# ATSAMG53 register map
Vendor: Microchip Technology; Series: SAMG53; File version: 0
CPU: CM4 r0p1, little endian, MPU, FPU, 4 interrupt priority bits
Registers are 32-bit, read-write, reset 0x0 unless marked. A register's access mark holds for its fields unless they carry their own. Offsets are from the block's base; [hi:lo] are bit positions; {n}, {i} and the like mark numbered series; 'fields as' and 'values as' point back to an identical list.

## SPI — Serial Peripheral Interface
Base 0x40008000; register names take the prefix SPI_
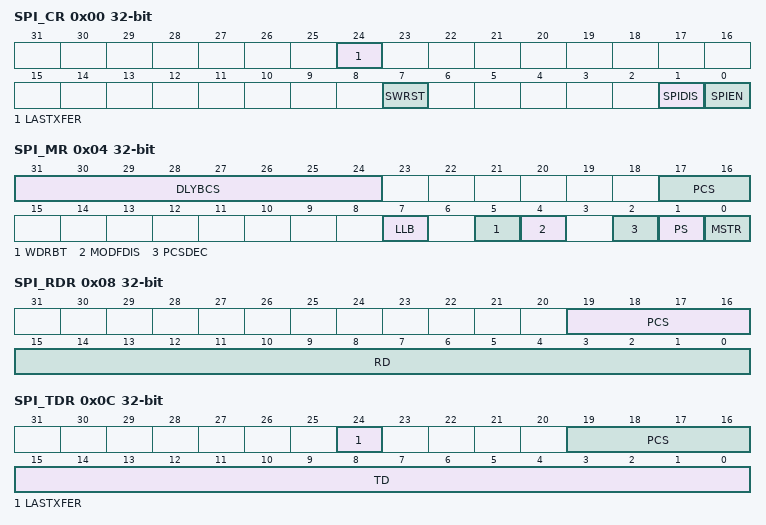
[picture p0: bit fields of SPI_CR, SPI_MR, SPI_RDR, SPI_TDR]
0x00 SPI_CR wo — Control Register
  [24] LASTXFER — Last Transfer
  [7] SWRST — SPI Software Reset
  [1] SPIDIS — SPI Disable
  [0] SPIEN — SPI Enable
0x04 SPI_MR — Mode Register
  [31:24] DLYBCS — Delay Between Chip Selects
  [17:16] PCS — Peripheral Chip Select
    2=NPCS0 (NPCS0 as Chip Select); 1=NPCS1 (NPCS1 as Chip Select)
  [7] LLB — Local Loopback Enable
  [5] WDRBT — Wait Data Read Before Transfer
  [4] MODFDIS — Mode Fault Detection
  [2] PCSDEC — Chip Select Decode
  [1] PS — Peripheral Select
  [0] MSTR — Master/Slave Mode
    1=MASTER; 0=SLAVE
0x08 SPI_RDR ro — Receive Data Register
  [19:16] PCS — Peripheral Chip Select
  [15:0] RD — Receive Data
0x0C SPI_TDR wo — Transmit Data Register
  [24] LASTXFER — Last Transfer
  [19:16] PCS — Peripheral Chip Select
    values as SPI_MR.PCS
  [15:0] TD — Transmit Data
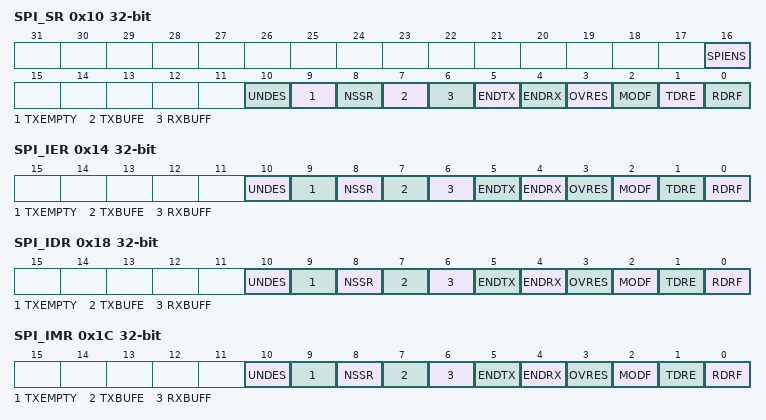
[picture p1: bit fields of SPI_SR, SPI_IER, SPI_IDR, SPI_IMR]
0x10 SPI_SR ro — Status Register
  [16] SPIENS — SPI Enable Status
  [10] UNDES — Underrun Error Status (slave mode only) (cleared on read)
  [9] TXEMPTY — Transmission Registers Empty (cleared by writing SPI_TDR)
  [8] NSSR — NSS Rising (cleared on read)
  [7] TXBUFE — TX Buffer Empty (cleared by writing SPI_TCR or SPI_TNCR)
  [6] RXBUFF — RX Buffer Full (cleared by writing SPI_RCR or SPI_RNCR)
  [5] ENDTX — End of TX buffer (cleared by writing SPI_TCR or SPI_TNCR)
  [4] ENDRX — End of RX buffer (cleared by writing SPI_RCR or SPI_RNCR)
  [3] OVRES — Overrun Error Status (cleared on read)
  [2] MODF — Mode Fault Error (cleared on read)
  [1] TDRE — Transmit Data Register Empty (cleared by writing SPI_TDR)
  [0] RDRF — Receive Data Register Full (cleared by reading SPI_RDR)
0x14 SPI_IER wo — Interrupt Enable Register
  [10] UNDES — Underrun Error Interrupt Enable
  [9] TXEMPTY — Transmission Registers Empty Enable
  [8] NSSR — NSS Rising Interrupt Enable
  [7] TXBUFE — Transmit Buffer Empty Interrupt Enable
  [6] RXBUFF — Receive Buffer Full Interrupt Enable
  [5] ENDTX — End of Transmit Buffer Interrupt Enable
  [4] ENDRX — End of Receive Buffer Interrupt Enable
  [3] OVRES — Overrun Error Interrupt Enable
  [2] MODF — Mode Fault Error Interrupt Enable
  [1] TDRE — SPI Transmit Data Register Empty Interrupt Enable
  [0] RDRF — Receive Data Register Full Interrupt Enable
0x18 SPI_IDR wo — Interrupt Disable Register
  [10] UNDES — Underrun Error Interrupt Disable
  [9] TXEMPTY — Transmission Registers Empty Disable
  [8] NSSR — NSS Rising Interrupt Disable
  [7] TXBUFE — Transmit Buffer Empty Interrupt Disable
  [6] RXBUFF — Receive Buffer Full Interrupt Disable
  [5] ENDTX — End of Transmit Buffer Interrupt Disable
  [4] ENDRX — End of Receive Buffer Interrupt Disable
  [3] OVRES — Overrun Error Interrupt Disable
  [2] MODF — Mode Fault Error Interrupt Disable
  [1] TDRE — SPI Transmit Data Register Empty Interrupt Disable
  [0] RDRF — Receive Data Register Full Interrupt Disable
0x1C SPI_IMR ro — Interrupt Mask Register
  [10] UNDES — Underrun Error Interrupt Mask
  [9] TXEMPTY — Transmission Registers Empty Mask
  [8] NSSR — NSS Rising Interrupt Mask
  [7] TXBUFE — Transmit Buffer Empty Interrupt Mask
  [6] RXBUFF — Receive Buffer Full Interrupt Mask
  [5] ENDTX — End of Transmit Buffer Interrupt Mask
  [4] ENDRX — End of Receive Buffer Interrupt Mask
  [3] OVRES — Overrun Error Interrupt Mask
  [2] MODF — Mode Fault Error Interrupt Mask
  [1] TDRE — SPI Transmit Data Register Empty Interrupt Mask
  [0] RDRF — Receive Data Register Full Interrupt Mask
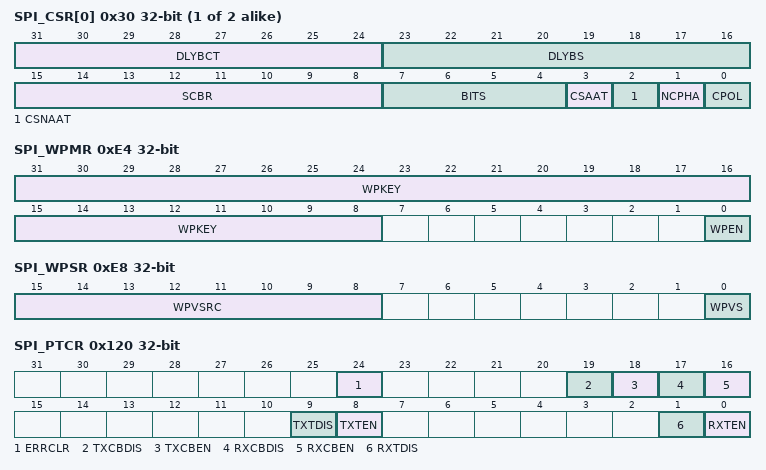
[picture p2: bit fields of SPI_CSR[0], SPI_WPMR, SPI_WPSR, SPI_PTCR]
{0x30+4i} SPI_CSR[{i}] (i=0..1) — Chip Select Register 0
  [31:24] DLYBCT — Delay Between Consecutive Transfers
  [23:16] DLYBS — Delay Before SPCK
  [15:8] SCBR — Serial Clock Baud Rate
  [7:4] BITS — Bits Per Transfer
    {v}=_{v+8}_BIT ({v+8} bits for transfer) (v=0..8)
  [3] CSAAT — Chip Select Active After Transfer
  [2] CSNAAT — Chip Select Not Active After Transfer (Ignored if CSAAT = 1)
  [1] NCPHA — Clock Phase
    1=VALID_LEADING_EDGE (Data is changed on the leading edge of SPCK and captured on the following edge of SPCK); 0=VALID_TRAILING_EDGE (Data is captured on the leading edge of SPCK and changed on the following edge of SPCK)
  [0] CPOL — Clock Polarity
    0=IDLE_LOW (The inactive state value of SPCK is logic level zero); 1=IDLE_HIGH (The inactive state value of SPCK is logic level one)
0xE4 SPI_WPMR — Write Protection Mode Register
  [31:8] WPKEY — Write Protection Key
    0x535049=PASSWD (Writing any other value in this field aborts the write operation of the WPEN bit.Always reads as 0.)
  [0] WPEN — Write Protection Enable
0xE8 SPI_WPSR ro — Write Protection Status Register
  [15:8] WPVSRC — Write Protection Violation Source
  [0] WPVS — Write Protection Violation Status
0x100 SPI_RPR — Receive Pointer Register
  [31:0] RXPTR
0x104 SPI_RCR — Receive Counter Register
  [15:0] RXCTR
0x108 SPI_TPR — Transmit Pointer Register
  [31:0] TXPTR — Transmit Counter Register
0x10C SPI_TCR — Transmit Counter Register
  [15:0] TXCTR
0x110 SPI_RNPR — Receive Next Pointer Register
  [31:0] RXNPTR — Receive Next Pointer
0x114 SPI_RNCR — Receive Next Counter Register
  [15:0] RXNCTR — Receive Next Counter
0x118 SPI_TNPR — Transmit Next Pointer Register
  [31:0] TXNPTR — Transmit Next Pointer
0x11C SPI_TNCR — Transmit Next Counter Register
  [15:0] TXNCTR — Transmit Counter Next
0x120 SPI_PTCR wo — Transfer Control Register
  [24] ERRCLR — Transfer Bus Error Clear
  [19] TXCBDIS — Transmitter Circular Buffer Disable
  [18] TXCBEN — Transmitter Circular Buffer Enable
  [17] RXCBDIS — Receiver Circular Buffer Disable
  [16] RXCBEN — Receiver Circular Buffer Enable
  [9] TXTDIS — Transmitter Transfer Disable
  [8] TXTEN — Transmitter Transfer Enable
  [1] RXTDIS — Receiver Transfer Disable
  [0] RXTEN — Receiver Transfer Enable
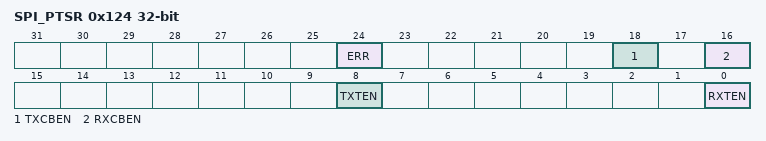
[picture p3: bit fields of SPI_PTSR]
0x124 SPI_PTSR ro — Transfer Status Register
  [24] ERR — Transfer Bus Error
  [18] TXCBEN — Transmitter Circular Buffer Enable
  [16] RXCBEN — Receiver Circular Buffer Enable
  [8] TXTEN — Transmitter Transfer Enable
  [0] RXTEN — Receiver Transfer Enable

## Notices in the file
Copyright (c) 2017 Microchip Technology Inc.
SPDX-License-Identifier: Apache-2.0
Licensed under the Apache License, Version 2.0 (the "License");
you may not use this file except in compliance with the License.
You may obtain a copy of the License at
http://www.apache.org/licenses/LICENSE-2.0
Unless required by applicable law or agreed to in writing, software
distributed under the License is distributed on an "AS IS" BASIS,
WITHOUT WARRANTIES OR CONDITIONS OF ANY KIND, either express or implied.
See the License for the specific language governing permissions and
limitations under the License.
